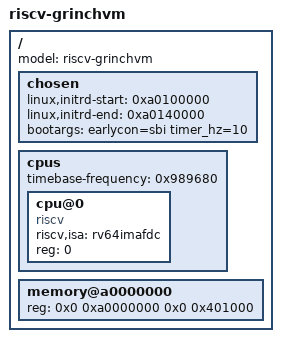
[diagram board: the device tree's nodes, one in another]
/dts-v1/;

/ {
	#address-cells = <2>;
	#size-cells = <2>;
	model = "riscv-grinchvm";

	chosen {
		/*
		 * Specify 256KB. Must be adjusted, once we have a huger
		 * ramdisk.
		 */
		linux,initrd-start = <0xa0100000>;
		linux,initrd-end = <0xa0140000>;
		bootargs = "earlycon=sbi timer_hz=10";
	};

	cpus {
		#address-cells = <1>;
		#size-cells = <0>;
		timebase-frequency = <0x989680>;

		cpu@0 {
			riscv,isa = "rv64imafdc";
			device_type = "cpu";
			compatible = "riscv";
			reg = <0>;
			status = "okay";
		};
	};

	memory@a0000000 {
		device_type = "memory";
		reg = <0x0 0xa0000000 0x0 0x401000>;
	};
};
